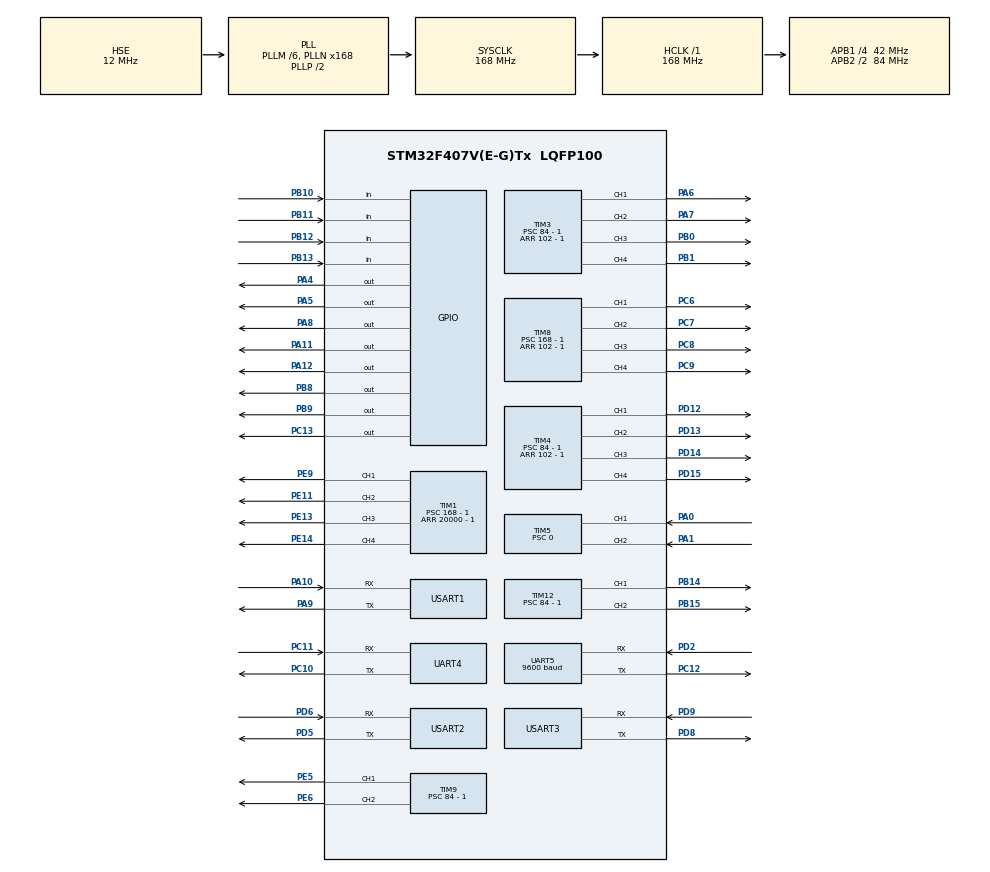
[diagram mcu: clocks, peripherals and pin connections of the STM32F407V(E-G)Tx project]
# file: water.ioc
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Dma.Request0=USART1_RX
Dma.Request1=USART1_TX
Dma.Request2=USART2_RX
Dma.Request3=USART2_TX
Dma.Request4=UART4_RX
Dma.Request5=UART4_TX
Dma.Request6=USART3_RX
Dma.Request7=USART3_TX
Dma.Request8=UART5_RX
Dma.Request9=UART5_TX
Dma.UART4_RX.4.Direction=DMA_PERIPH_TO_MEMORY
Dma.UART4_RX.4.FIFOMode=DMA_FIFOMODE_DISABLE
Dma.UART4_RX.4.Instance=DMA1_Stream2
Dma.UART4_RX.4.MemDataAlignment=DMA_MDATAALIGN_BYTE
Dma.UART4_RX.4.MemInc=DMA_MINC_ENABLE
Dma.UART4_RX.4.Mode=DMA_CIRCULAR
Dma.UART4_RX.4.PeriphDataAlignment=DMA_PDATAALIGN_BYTE
Dma.UART4_RX.4.PeriphInc=DMA_PINC_DISABLE
Dma.UART4_RX.4.Priority=DMA_PRIORITY_LOW
Dma.UART4_TX.5.Direction=DMA_MEMORY_TO_PERIPH
Dma.UART4_TX.5.FIFOMode=DMA_FIFOMODE_DISABLE
Dma.UART4_TX.5.Instance=DMA1_Stream4
Dma.UART4_TX.5.MemDataAlignment=DMA_MDATAALIGN_BYTE
Dma.UART4_TX.5.MemInc=DMA_MINC_ENABLE
Dma.UART4_TX.5.Mode=DMA_NORMAL
Dma.UART4_TX.5.PeriphDataAlignment=DMA_PDATAALIGN_BYTE
Dma.UART4_TX.5.PeriphInc=DMA_PINC_DISABLE
Dma.UART4_TX.5.Priority=DMA_PRIORITY_LOW
Dma.UART5_RX.8.Direction=DMA_PERIPH_TO_MEMORY
Dma.UART5_RX.8.FIFOMode=DMA_FIFOMODE_DISABLE
Dma.UART5_RX.8.Instance=DMA1_Stream0
Dma.UART5_RX.8.MemDataAlignment=DMA_MDATAALIGN_BYTE
Dma.UART5_RX.8.MemInc=DMA_MINC_ENABLE
Dma.UART5_RX.8.Mode=DMA_CIRCULAR
Dma.UART5_RX.8.PeriphDataAlignment=DMA_PDATAALIGN_BYTE
Dma.UART5_RX.8.PeriphInc=DMA_PINC_DISABLE
Dma.UART5_RX.8.Priority=DMA_PRIORITY_LOW
Dma.UART5_TX.9.Direction=DMA_MEMORY_TO_PERIPH
Dma.UART5_TX.9.FIFOMode=DMA_FIFOMODE_DISABLE
Dma.UART5_TX.9.Instance=DMA1_Stream7
Dma.UART5_TX.9.MemDataAlignment=DMA_MDATAALIGN_BYTE
Dma.UART5_TX.9.MemInc=DMA_MINC_ENABLE
Dma.UART5_TX.9.Mode=DMA_NORMAL
Dma.UART5_TX.9.PeriphDataAlignment=DMA_PDATAALIGN_BYTE
Dma.UART5_TX.9.PeriphInc=DMA_PINC_DISABLE
Dma.UART5_TX.9.Priority=DMA_PRIORITY_LOW
Dma.USART1_RX.0.Direction=DMA_PERIPH_TO_MEMORY
Dma.USART1_RX.0.FIFOMode=DMA_FIFOMODE_DISABLE
Dma.USART1_RX.0.Instance=DMA2_Stream2
Dma.USART1_RX.0.MemDataAlignment=DMA_MDATAALIGN_BYTE
Dma.USART1_RX.0.MemInc=DMA_MINC_ENABLE
Dma.USART1_RX.0.Mode=DMA_CIRCULAR
Dma.USART1_RX.0.PeriphDataAlignment=DMA_PDATAALIGN_BYTE
Dma.USART1_RX.0.PeriphInc=DMA_PINC_DISABLE
Dma.USART1_RX.0.Priority=DMA_PRIORITY_LOW
Dma.USART1_TX.1.Direction=DMA_MEMORY_TO_PERIPH
Dma.USART1_TX.1.FIFOMode=DMA_FIFOMODE_DISABLE
Dma.USART1_TX.1.Instance=DMA2_Stream7
Dma.USART1_TX.1.MemDataAlignment=DMA_MDATAALIGN_BYTE
Dma.USART1_TX.1.MemInc=DMA_MINC_ENABLE
Dma.USART1_TX.1.Mode=DMA_NORMAL
Dma.USART1_TX.1.PeriphDataAlignment=DMA_PDATAALIGN_BYTE
Dma.USART1_TX.1.PeriphInc=DMA_PINC_DISABLE
Dma.USART1_TX.1.Priority=DMA_PRIORITY_LOW
Dma.USART2_RX.2.Direction=DMA_PERIPH_TO_MEMORY
Dma.USART2_RX.2.FIFOMode=DMA_FIFOMODE_DISABLE
Dma.USART2_RX.2.Instance=DMA1_Stream5
Dma.USART2_RX.2.MemDataAlignment=DMA_MDATAALIGN_BYTE
Dma.USART2_RX.2.MemInc=DMA_MINC_ENABLE
Dma.USART2_RX.2.Mode=DMA_CIRCULAR
Dma.USART2_RX.2.PeriphDataAlignment=DMA_PDATAALIGN_BYTE
Dma.USART2_RX.2.PeriphInc=DMA_PINC_DISABLE
Dma.USART2_RX.2.Priority=DMA_PRIORITY_LOW
Dma.USART2_TX.3.Direction=DMA_MEMORY_TO_PERIPH
Dma.USART2_TX.3.FIFOMode=DMA_FIFOMODE_DISABLE
Dma.USART2_TX.3.Instance=DMA1_Stream6
Dma.USART2_TX.3.MemDataAlignment=DMA_MDATAALIGN_BYTE
Dma.USART2_TX.3.MemInc=DMA_MINC_ENABLE
Dma.USART2_TX.3.Mode=DMA_NORMAL
Dma.USART2_TX.3.PeriphDataAlignment=DMA_PDATAALIGN_BYTE
Dma.USART2_TX.3.PeriphInc=DMA_PINC_DISABLE
Dma.USART2_TX.3.Priority=DMA_PRIORITY_LOW
Dma.USART3_RX.6.Direction=DMA_PERIPH_TO_MEMORY
Dma.USART3_RX.6.FIFOMode=DMA_FIFOMODE_DISABLE
Dma.USART3_RX.6.Instance=DMA1_Stream1
Dma.USART3_RX.6.MemDataAlignment=DMA_MDATAALIGN_BYTE
Dma.USART3_RX.6.MemInc=DMA_MINC_ENABLE
Dma.USART3_RX.6.Mode=DMA_CIRCULAR
Dma.USART3_RX.6.PeriphDataAlignment=DMA_PDATAALIGN_BYTE
Dma.USART3_RX.6.PeriphInc=DMA_PINC_DISABLE
Dma.USART3_RX.6.Priority=DMA_PRIORITY_LOW
Dma.USART3_TX.7.Direction=DMA_MEMORY_TO_PERIPH
Dma.USART3_TX.7.FIFOMode=DMA_FIFOMODE_DISABLE
Dma.USART3_TX.7.Instance=DMA1_Stream3
Dma.USART3_TX.7.MemDataAlignment=DMA_MDATAALIGN_BYTE
Dma.USART3_TX.7.MemInc=DMA_MINC_ENABLE
Dma.USART3_TX.7.Mode=DMA_NORMAL
Dma.USART3_TX.7.PeriphDataAlignment=DMA_PDATAALIGN_BYTE
Dma.USART3_TX.7.PeriphInc=DMA_PINC_DISABLE
Dma.USART3_TX.7.Priority=DMA_PRIORITY_LOW
Mcu.Family=STM32F4
Mcu.Name=STM32F407V(E-G)Tx
Mcu.Package=LQFP100
NVIC.DMA1_Stream0_IRQn=true\:0\:0\:false\:false\:true\:false\:true\:true
NVIC.DMA1_Stream1_IRQn=true\:0\:0\:false\:false\:true\:false\:true\:true
NVIC.DMA1_Stream2_IRQn=true\:0\:0\:false\:false\:true\:false\:true\:true
NVIC.DMA1_Stream3_IRQn=true\:0\:0\:false\:false\:true\:false\:true\:true
NVIC.DMA1_Stream4_IRQn=true\:0\:0\:false\:false\:true\:false\:true\:true
NVIC.DMA1_Stream5_IRQn=true\:0\:0\:false\:false\:true\:false\:true\:true
NVIC.DMA1_Stream6_IRQn=true\:0\:0\:false\:false\:true\:false\:true\:true
NVIC.DMA1_Stream7_IRQn=true\:0\:0\:false\:false\:true\:false\:true\:true
NVIC.DMA2_Stream2_IRQn=true\:0\:0\:false\:false\:true\:false\:true\:true
NVIC.DMA2_Stream7_IRQn=true\:0\:0\:false\:false\:true\:false\:true\:true
NVIC.PriorityGroup=NVIC_PRIORITYGROUP_4
NVIC.TIM6_DAC_IRQn=true\:0\:0\:false\:false\:true\:true\:true\:true
NVIC.UART4_IRQn=true\:0\:0\:false\:false\:true\:true\:true\:true
NVIC.UART5_IRQn=true\:0\:0\:false\:false\:true\:true\:true\:true
NVIC.USART1_IRQn=true\:0\:0\:false\:false\:true\:true\:true\:true
NVIC.USART2_IRQn=true\:0\:0\:false\:false\:true\:true\:true\:true
NVIC.USART3_IRQn=true\:0\:0\:false\:false\:true\:true\:true\:true
PA0-WKUP.Signal=S_TIM5_CH1
PA1.Signal=S_TIM5_CH2
PA10.Mode=Asynchronous
PA10.Signal=USART1_RX
PA11.GPIO_PuPd=GPIO_NOPULL
PA11.Signal=GPIO_Output
PA12.GPIO_PuPd=GPIO_NOPULL
PA12.Signal=GPIO_Output
PA13.Mode=Serial_Wire
PA13.Signal=SYS_JTMS-SWDIO
PA14.Mode=Serial_Wire
PA14.Signal=SYS_JTCK-SWCLK
PA4.Signal=GPIO_Output
PA5.GPIO_PuPd=GPIO_NOPULL
PA5.Signal=GPIO_Output
PA6.Signal=S_TIM3_CH1
PA7.Signal=S_TIM3_CH2
PA8.GPIO_PuPd=GPIO_NOPULL
PA8.Signal=GPIO_Output
PA9.Mode=Asynchronous
PA9.Signal=USART1_TX
PB0.Signal=S_TIM3_CH3
PB1.Signal=S_TIM3_CH4
PB10.Signal=GPIO_Input
PB11.Signal=GPIO_Input
PB12.Signal=GPIO_Input
PB13.Signal=GPIO_Input
PB14.Signal=S_TIM12_CH1
PB15.Signal=S_TIM12_CH2
PB8.Signal=GPIO_Output
PB9.Signal=GPIO_Output
PC10.Mode=Asynchronous
PC10.Signal=UART4_TX
PC11.Mode=Asynchronous
PC11.Signal=UART4_RX
PC12.Mode=Asynchronous
PC12.Signal=UART5_TX
PC13-ANTI_TAMP.Signal=GPIO_Output
PC6.Signal=S_TIM8_CH1
PC7.Signal=S_TIM8_CH2
PC8.Signal=S_TIM8_CH3
PC9.Signal=S_TIM8_CH4
PD12.Signal=S_TIM4_CH1
PD13.Signal=S_TIM4_CH2
PD14.Signal=S_TIM4_CH3
PD15.Signal=S_TIM4_CH4
PD2.Mode=Asynchronous
PD2.Signal=UART5_RX
PD5.Mode=Asynchronous
PD5.Signal=USART2_TX
PD6.Mode=Asynchronous
PD6.Signal=USART2_RX
PD8.Mode=Asynchronous
PD8.Signal=USART3_TX
PD9.Mode=Asynchronous
PD9.Signal=USART3_RX
PE11.Signal=S_TIM1_CH2
PE13.Signal=S_TIM1_CH3
PE14.Signal=S_TIM1_CH4
PE5.Signal=S_TIM9_CH1
PE6.Signal=S_TIM9_CH2
PE9.Signal=S_TIM1_CH1
PH0-OSC_IN.Mode=HSE-External-Oscillator
PH0-OSC_IN.Signal=RCC_OSC_IN
PH1-OSC_OUT.Mode=HSE-External-Oscillator
PH1-OSC_OUT.Signal=RCC_OSC_OUT
ProjectManager.HeapSize=0x200
ProjectManager.StackSize=0x400
ProjectManager.TargetToolchain=MDK-ARM V5.32
RCC.48MHZClocksFreq_Value=84000000
RCC.AHBFreq_Value=168000000
RCC.APB1CLKDivider=RCC_HCLK_DIV4
RCC.APB1Freq_Value=42000000
RCC.APB1TimFreq_Value=84000000
RCC.APB2CLKDivider=RCC_HCLK_DIV2
RCC.APB2Freq_Value=84000000
RCC.APB2TimFreq_Value=168000000
RCC.CortexFreq_Value=168000000
RCC.HCLKFreq_Value=168000000
RCC.HSE_VALUE=12000000
RCC.HSI_VALUE=16000000
RCC.LSE_VALUE=32768
RCC.PLLM=6
RCC.PLLN=168
RCC.PLLSourceVirtual=RCC_PLLSOURCE_HSE
RCC.SYSCLKFreq_VALUE=168000000
RCC.SYSCLKSource=RCC_SYSCLKSOURCE_PLLCLK
RCC.VCOOutputFreq_Value=336000000
SH.S_TIM12_CH1.0=TIM12_CH1,PWM Generation1 CH1
SH.S_TIM12_CH2.0=TIM12_CH2,PWM Generation2 CH2
SH.S_TIM1_CH1.0=TIM1_CH1,PWM Generation1 CH1
SH.S_TIM1_CH2.0=TIM1_CH2,PWM Generation2 CH2
SH.S_TIM1_CH3.0=TIM1_CH3,PWM Generation3 CH3
SH.S_TIM1_CH4.0=TIM1_CH4,PWM Generation4 CH4
SH.S_TIM3_CH1.0=TIM3_CH1,PWM Generation1 CH1
SH.S_TIM3_CH2.0=TIM3_CH2,PWM Generation2 CH2
SH.S_TIM3_CH3.0=TIM3_CH3,PWM Generation3 CH3
SH.S_TIM3_CH4.0=TIM3_CH4,PWM Generation4 CH4
SH.S_TIM4_CH1.0=TIM4_CH1,PWM Generation1 CH1
SH.S_TIM4_CH2.0=TIM4_CH2,PWM Generation2 CH2
SH.S_TIM4_CH3.0=TIM4_CH3,PWM Generation3 CH3
SH.S_TIM4_CH4.0=TIM4_CH4,PWM Generation4 CH4
SH.S_TIM5_CH1.0=TIM5_CH1,Encoder_Interface
SH.S_TIM5_CH2.0=TIM5_CH2,Encoder_Interface
SH.S_TIM8_CH1.0=TIM8_CH1,PWM Generation1 CH1
SH.S_TIM8_CH2.0=TIM8_CH2,PWM Generation2 CH2
SH.S_TIM8_CH3.0=TIM8_CH3,PWM Generation3 CH3
SH.S_TIM8_CH4.0=TIM8_CH4,PWM Generation4 CH4
SH.S_TIM9_CH1.0=TIM9_CH1,PWM Generation1 CH1
SH.S_TIM9_CH2.0=TIM9_CH2,PWM Generation2 CH2
TIM1.AutoReloadPreload=TIM_AUTORELOAD_PRELOAD_ENABLE
TIM1.Channel-PWM\ Generation1\ CH1=TIM_CHANNEL_1
TIM1.Channel-PWM\ Generation2\ CH2=TIM_CHANNEL_2
TIM1.Channel-PWM\ Generation3\ CH3=TIM_CHANNEL_3
TIM1.Channel-PWM\ Generation4\ CH4=TIM_CHANNEL_4
TIM1.Period=20000 - 1
TIM1.Prescaler=168 - 1
TIM12.AutoReloadPreload=TIM_AUTORELOAD_PRELOAD_ENABLE
TIM12.Channel-PWM\ Generation1\ CH1=TIM_CHANNEL_1
TIM12.Channel-PWM\ Generation2\ CH2=TIM_CHANNEL_2
TIM12.Period=102 - 1
TIM12.Prescaler=84 - 1
TIM2.AutoReloadPreload=TIM_AUTORELOAD_PRELOAD_ENABLE
TIM2.Period=102 - 1
TIM2.Prescaler=84 - 1
TIM3.AutoReloadPreload=TIM_AUTORELOAD_PRELOAD_ENABLE
TIM3.Channel-PWM\ Generation1\ CH1=TIM_CHANNEL_1
TIM3.Channel-PWM\ Generation2\ CH2=TIM_CHANNEL_2
TIM3.Channel-PWM\ Generation3\ CH3=TIM_CHANNEL_3
TIM3.Channel-PWM\ Generation4\ CH4=TIM_CHANNEL_4
TIM3.Period=102 - 1
TIM3.Prescaler=84 - 1
TIM4.AutoReloadPreload=TIM_AUTORELOAD_PRELOAD_ENABLE
TIM4.Channel-PWM\ Generation1\ CH1=TIM_CHANNEL_1
TIM4.Channel-PWM\ Generation2\ CH2=TIM_CHANNEL_2
TIM4.Channel-PWM\ Generation3\ CH3=TIM_CHANNEL_3
TIM4.Channel-PWM\ Generation4\ CH4=TIM_CHANNEL_4
TIM4.Period=102 - 1
TIM4.Prescaler=84 - 1
TIM5.AutoReloadPreload=TIM_AUTORELOAD_PRELOAD_ENABLE
TIM5.EncoderMode=TIM_ENCODERMODE_TI12
TIM5.Period=65535
TIM5.Prescaler=0
TIM6.AutoReloadPreload=TIM_AUTORELOAD_PRELOAD_ENABLE
TIM6.Period=10000 - 1
TIM6.Prescaler=84 - 1
TIM8.AutoReloadPreload=TIM_AUTORELOAD_PRELOAD_ENABLE
TIM8.Channel-PWM\ Generation1\ CH1=TIM_CHANNEL_1
TIM8.Channel-PWM\ Generation2\ CH2=TIM_CHANNEL_2
TIM8.Channel-PWM\ Generation3\ CH3=TIM_CHANNEL_3
TIM8.Channel-PWM\ Generation4\ CH4=TIM_CHANNEL_4
TIM8.Period=102 - 1
TIM8.Prescaler=168 - 1
TIM9.Channel-PWM\ Generation1\ CH1=TIM_CHANNEL_1
TIM9.Channel-PWM\ Generation2\ CH2=TIM_CHANNEL_2
TIM9.Period=102 - 1
TIM9.Prescaler=84 - 1
UART4.VirtualMode=Asynchronous
UART5.BaudRate=9600
UART5.VirtualMode=Asynchronous
USART1.VirtualMode=VM_ASYNC
USART2.VirtualMode=VM_ASYNC
USART3.VirtualMode=VM_ASYNC
VP_TIM12_VS_ClockSourceINT.Mode=Internal
VP_TIM1_VS_ClockSourceINT.Mode=Internal
VP_TIM2_VS_ClockSourceINT.Mode=Internal
VP_TIM3_VS_ClockSourceINT.Mode=Internal
VP_TIM4_VS_ClockSourceINT.Mode=Internal
VP_TIM6_VS_ClockSourceINT.Mode=Enable_Timer
VP_TIM8_VS_ClockSourceINT.Mode=Internal
VP_TIM9_VS_ClockSourceINT.Mode=Internal
board=custom

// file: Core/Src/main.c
/* USER CODE BEGIN Header */
/**
  ******************************************************************************
  * @file           : main.c
  * @brief          : Main program body
  ******************************************************************************
  * @attention
  *
  * Copyright (c) 2025 STMicroelectronics.
  * All rights reserved.
  *
  * This software is licensed under terms that can be found in the LICENSE file
  * in the root directory of this software component.
  * If no LICENSE file comes with this software, it is provided AS-IS.
  *
  ******************************************************************************
  */
/* USER CODE END Header */
#include "main.h"
#include "dma.h"
#include "tim.h"
#include "usart.h"
#include "gpio.h"

/* USER CODE BEGIN Includes */
#include "system.h"
/* USER CODE END Includes */

void SystemClock_Config(void);

int main(void)
{

  /* MCU Configuration--------------------------------------------------------*/

  /* Reset of all peripherals, Initializes the Flash interface and the Systick. */
  HAL_Init();

  /* Configure the system clock */
  SystemClock_Config();

  /* Initialize all configured peripherals */
  MX_GPIO_Init();
  MX_DMA_Init();
  MX_TIM6_Init();
  MX_UART4_Init();
  MX_UART5_Init();
  MX_USART1_UART_Init();
  MX_USART2_UART_Init();
  MX_TIM1_Init();
  MX_TIM2_Init();
  MX_TIM3_Init();
  MX_TIM4_Init();
  MX_TIM8_Init();
  MX_TIM12_Init();
  MX_TIM5_Init();
  MX_USART3_UART_Init();
  MX_TIM9_Init();
  /* USER CODE BEGIN 2 */
  APP_Init();
  /* USER CODE END 2 */

  /* Infinite loop */
  /* USER CODE BEGIN WHILE */
  while (1)
  {
    APP_MAIN();
    /* USER CODE END WHILE */

  }
}

void SystemClock_Config(void)
{
  RCC_OscInitTypeDef RCC_OscInitStruct = {0};
  RCC_ClkInitTypeDef RCC_ClkInitStruct = {0};

  /** Configure the main internal regulator output voltage
  */
  __HAL_RCC_PWR_CLK_ENABLE();
  __HAL_PWR_VOLTAGESCALING_CONFIG(PWR_REGULATOR_VOLTAGE_SCALE1);

  /** Initializes the RCC Oscillators according to the specified parameters
  * in the RCC_OscInitTypeDef structure.
  */
  RCC_OscInitStruct.OscillatorType = RCC_OSCILLATORTYPE_HSE;
  RCC_OscInitStruct.HSEState = RCC_HSE_ON;
  RCC_OscInitStruct.PLL.PLLState = RCC_PLL_ON;
  RCC_OscInitStruct.PLL.PLLSource = RCC_PLLSOURCE_HSE;
  RCC_OscInitStruct.PLL.PLLM = 6;
  RCC_OscInitStruct.PLL.PLLN = 168;
  RCC_OscInitStruct.PLL.PLLP = RCC_PLLP_DIV2;
  RCC_OscInitStruct.PLL.PLLQ = 4;
  if (HAL_RCC_OscConfig(&RCC_OscInitStruct) != HAL_OK)
  {
    Error_Handler();
  }

  /** Initializes the CPU, AHB and APB buses clocks
  */
  RCC_ClkInitStruct.ClockType = RCC_CLOCKTYPE_HCLK|RCC_CLOCKTYPE_SYSCLK
                              |RCC_CLOCKTYPE_PCLK1|RCC_CLOCKTYPE_PCLK2;
  RCC_ClkInitStruct.SYSCLKSource = RCC_SYSCLKSOURCE_PLLCLK;
  RCC_ClkInitStruct.AHBCLKDivider = RCC_SYSCLK_DIV1;
  RCC_ClkInitStruct.APB1CLKDivider = RCC_HCLK_DIV4;
  RCC_ClkInitStruct.APB2CLKDivider = RCC_HCLK_DIV2;

  if (HAL_RCC_ClockConfig(&RCC_ClkInitStruct, FLASH_LATENCY_5) != HAL_OK)
  {
    Error_Handler();
  }
}

void Error_Handler(void)
{
  __disable_irq();
  while (1)
  {
  }
}
